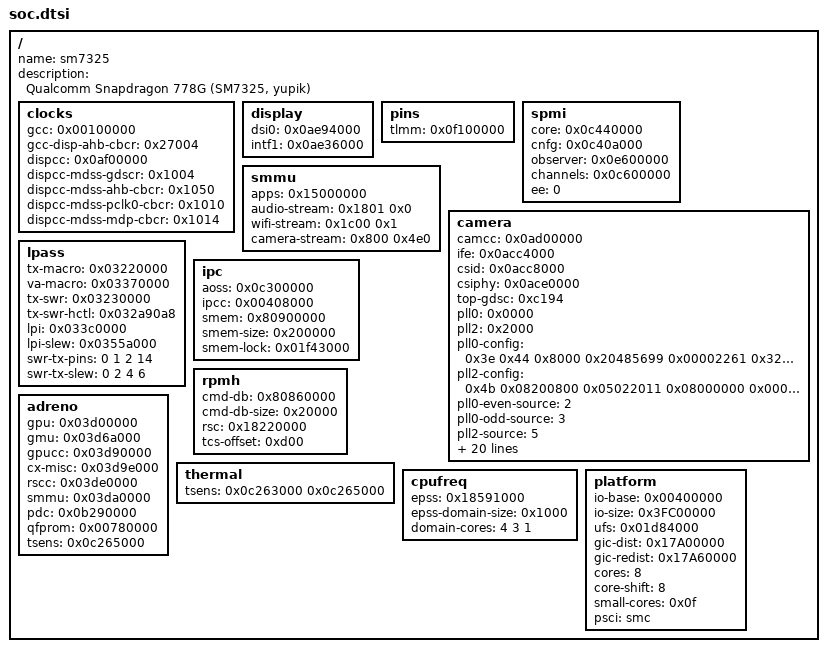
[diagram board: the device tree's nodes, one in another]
/dts-v1/;

// Qualcomm Snapdragon 778G. What every board with this SoC shares: where its blocks are.
// Sources: the SoC's device tree (yupik*.dtsi) and Linux's clock drivers (dispcc-yupik.c).
/ {
	name = "sm7325";
	description = "Qualcomm Snapdragon 778G (SM7325, yupik)";

	clocks {
		gcc = <0x00100000>;             // clock-controller@100000
		gcc-disp-ahb-cbcr = <0x27004>;  // gcc_disp_ahb_clk
		dispcc = <0x0af00000>;          // clock-controller@af00000
		dispcc-mdss-gdscr = <0x1004>;   // the display block's power switch (mdss_core_gdsc)
		dispcc-mdss-ahb-cbcr = <0x1050>; // disp_cc_mdss_ahb_clk
		dispcc-mdss-pclk0-cbcr = <0x1010>; // disp_cc_mdss_pclk0_clk  } only looked at, by display_probe=1
		dispcc-mdss-mdp-cbcr = <0x1014>; // disp_cc_mdss_mdp_clk    }
	};

	display {
		dsi0 = <0x0ae94000>;            // mdss_dsi0, reg "dsi_ctrl" (DSI controller 2.5)
		intf1 = <0x0ae36000>;           // mdss_dsi0, reg "mdp_intf_base": the interface the panel hangs on
	};

	// The SoC's own pins (TLMM, pinctrl@f000000): what the drivers of the touch controller, the speaker
	// amplifier, the haptic motor and the cameras drive.
	pins {
		tlmm = <0x0f100000>;            // GPIO 0's registers: 0x100000 into the block; 0x1000 for each GPIO
	};

	// The PMIC arbiter: the way to the power management chips on the SPMI bus (qcom,spmi-pmic-arb, by
	// reg-names "core", "cnfg", "obsrvr" and "chnls"). The keys are read through it; the flashlight and the
	// cameras' supply switch are written through it.
	spmi {
		core = <0x0c440000>;            // the version, and which peripheral each channel is
		cnfg = <0x0c40a000>;            // which system may write through each channel
		observer = <0x0e600000>;        // reads
		channels = <0x0c600000>;        // writes
		ee = <0>;                       // qcom,ee: which of the arbiter's systems this one is
	};

	// The SMMU between the SoC's devices and memory (the GPU has its own, in adreno { }).
	smmu {
		apps = <0x15000000>;            // apps_smmu
		audio-stream = <0x1801 0x0>;    // qcom,msm-audio-ion: iommus <&apps_smmu 0x1801 0x0>
		wifi-stream = <0x1c00 0x1>;     // the Wi-Fi DSP's (qcom,wpss): iommus <&apps_smmu 0x1c00 0x1>
		camera-stream = <0x800 0x4e0>;  // msm_cam_smmu_ife: iommus 0x800 .. 0xce0, mask 0x4e0
	};

	// The camera subsystem's blocks (yupik-camera.dtsi), for "camera-sm7325".
	camera {
		camcc = <0x0ad00000>;           // the camera clock controller
		ife = <0x0acc4000>;             // the first IFE "lite", which the driver takes frames through
		csid = <0x0acc8000>;            // its CSI decoder
		csiphy = <0x0ace0000>;          // CSIPHY 0; the others follow at 0x2000
		// Where camcc has what the driver switches (camcc-yupik.c), and the GCC its camera clocks (gcc-yupik.c).
		top-gdsc = <0xc194>;            // titan_top_gdsc
		pll0 = <0x0000>;                // cam_cc_pll0 (Lucid)
		pll2 = <0x2000>;                // cam_cc_pll2 (Zonda)
		// cam_cc_pll0_config ("1200MHz Configuration"; CAL_L as clk-alpha-pll.c's default) and
		// cam_cc_pll2_config ("1440MHz Configuration"); their outputs' places in cam_cc_parent_map_*
		pll0-config = <0x3e 0x44 0x8000 0x20485699 0x00002261 0x329a299c 0x00003101 0x00000805 0x00000000>;
		pll2-config = <0x4b 0x08200800 0x05022011 0x08000000 0x00000301>;
		pll0-even-source = <2>;
		pll0-odd-source = <3>;
		pll2-source = <5>;
		mclk-rcg = <0xe000 0xe01c 0xe038 0xe054>;       // cam_cc_mclkN_clk_src
		mclk-branch = <0xe018 0xe034 0xe050 0xe06c>;    // cam_cc_mclkN_clk
		csiphy-branch = <0xe0c8 0xe0ec 0xe110 0xe138>;  // cam_cc_csiphyN_clk
		csiphy-timer-rcg = <0xe0ac 0xe0d0 0xe0f4 0xe11c>;       // cam_cc_csiNphytimer_clk_src
		csiphy-timer-branch = <0xe0c4 0xe0e8 0xe10c 0xe134>;    // cam_cc_csiNphytimer_clk
		slow-ahb-rcg = <0x7058>;        // cam_cc_slow_ahb_clk_src
		camnoc-axi-rcg = <0xc124>;      // cam_cc_camnoc_axi_clk_src
		cphy-rx-rcg = <0xa064>;         // cam_cc_cphy_rx_clk_src
		ife-csid-rcg = <0xc020>;        // cam_cc_ife_lite_0_csid_clk_src
		ife-rcg = <0xc004>;             // cam_cc_ife_lite_0_clk_src
		cpas-ahb-branch = <0xc11c>;     // cam_cc_cpas_ahb_clk
		camnoc-axi-branch = <0xc140>;   // cam_cc_camnoc_axi_clk
		ife-csid-branch = <0xc038>;     // cam_cc_ife_lite_0_csid_clk
		ife-cphy-rx-branch = <0xc040>;  // cam_cc_ife_lite_0_cphy_rx_clk
		ife-branch = <0xc01c>;          // cam_cc_ife_lite_0_clk
		gcc-ahb-branch = <0x26004>;     // gcc_camera_ahb_clk
		gcc-xo-branch = <0x26028>;      // gcc_camera_xo_clk
		gcc-hf-axi-branch = <0x26010>;  // gcc_camera_hf_axi_clk
		gcc-sf-axi-branch = <0x2601c>;  // gcc_camera_sf_axi_clk
	};

	// The low-power audio subsystem's blocks on the microphones' path (yupik-audio.dtsi), for "mic-wcd938x".
	lpass {
		tx-macro = <0x03220000>;        // tx-macro@3220000
		va-macro = <0x03370000>;        // va-macro@3370000
		tx-swr = <0x03230000>;          // the TX SoundWire master
		tx-swr-hctl = <0x032a90a8>;     // its hardware control register (qcom,swrm-hctl-reg)
		lpi = <0x033c0000>;             // lpi_pinctrl@33c0000: the subsystem's own pins
		lpi-slew = <0x0355a000>;        // their slew rates (qcom,slew-reg)
		swr-tx-pins = <0 1 2 14>;       // the TX SoundWire's: clock, data 0, 1 and 2 (lpi_pinctrl's tx_swr_* groups)
		swr-tx-slew = <0 2 4 6>;        // each one's slew field (pinctrl-lpi.c: the pins' slew_offset)
	};

	// The way to the SoC's other processors: the audio DSP and the Wi-Fi radio are reached through these.
	ipc {
		aoss = <0x0c300000>;            // qmp_aop (qcom,qmp-mbox): the always-on processor's mailbox
		ipcc = <0x00408000>;            // ipcc_mproc (qcom,ipcc): what the processors ring each other through
		smem = <0x80900000>;            // smem_mem: the memory they share
		smem-size = <0x200000>;
		smem-lock = <0x01f43000>;       // tcsr_mutex 3 (0x1f40000 + 3 x 0x1000): the lock on its allocations
	};

	// RPMh, for the memory bandwidth vote (feature "ddr-rpmh").
	rpmh {
		cmd-db = <0x80860000>;          // reserved-memory, compatible "qcom,cmd-db": the resources' names and addresses
		cmd-db-size = <0x20000>;
		rsc = <0x18220000>;             // apps_rsc (qcom,rpmh-rsc), reg "drv-2": the application processor's sequencer
		tcs-offset = <0xd00>;           // qcom,tcs-offset
	};

	// The Adreno's blocks, for the feature "gpu-a660" (qcom,kgsl-3d0 and qcom,gmu, by their reg-names).
	// What differs from one phone to the next -- the chip, its fuses, its speeds -- is the board's gpu { }.
	adreno {
		gpu = <0x03d00000>;             // qcom,kgsl-3d0, reg "kgsl_3d0_reg_memory": the 3D core
		gmu = <0x03d6a000>;             // qcom,gmu, reg "kgsl_gmu_reg"
		gpucc = <0x03d90000>;           // the GPU's clock controller (clock-controller@3d90000)
		cx-misc = <0x03d9e000>;         // qcom,kgsl-3d0, reg "cx-misc"
		rscc = <0x03de0000>;            // qcom,kgsl-3d0, reg "rscc": the GMU's RPMh channel
		smmu = <0x03da0000>;            // the GPU's SMMU (kgsl-smmu@3da0000)
		pdc = <0x0b290000>;             // qcom,gmu, reg "kgsl_gmu_pdc_cfg"
		qfprom = <0x00780000>;          // the fuses (qfprom@780000), where the board's gpu { } finds its bins
		tsens = <0x0c265000>;           // the TSENS controller with the GPU's two sensors (gpuss-0, gpuss-1)
	};

	thermal {
		tsens = <0x0c263000 0x0c265000>; // tsens0 and tsens1, reg "tsens_tm_physical"
	};

	cpufreq {
		epss = <0x18591000>;            // cpufreq-hw: one block of registers a group of cores
		epss-domain-size = <0x1000>;
		domain-cores = <4 3 1>;         // the cores of each group, in the cores' order (qcom,freq-domain): small, big, prime
	};

	// What the loader tells the kernel of the machine (loader/src/platform.h, struct platform).
	platform {
		io-base = <0x00400000>;         // one window over the SoC's peripherals; never 0
		io-size = <0x3FC00000>;
		ufs = <0x01d84000>;             // ufshc@1d84000, reg "ufs_mem": the UFS host controller
		gic-dist = <0x17A00000>;        // interrupt-controller@17a00000 (arm,gic-v3): reg, first entry
		gic-redist = <0x17A60000>;      // ... second entry
		cores = <8>;                    // the cpu@ nodes
		core-shift = <8>;               // their reg is 0x000, 0x100 ...: MPIDR's second affinity field
		small-cores = <0x0f>;           // a bit a core of the lowest capacity-dmips-mhz: cores 0 to 3 (Cortex-A55)
		psci = "smc";                   // psci: method
	};
};
